# HT32F175x register map
File version: 1.0
Registers are 32-bit, read-write, reset 0x0 unless marked. A register's access mark holds for its fields unless they carry their own. Offsets are from the block's base; [hi:lo] are bit positions; {n}, {i} and the like mark numbered series.

## BFTM0
Base 0x40076000
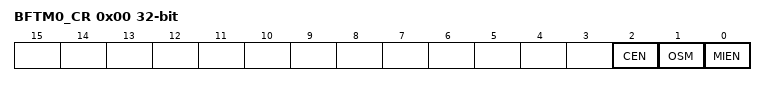
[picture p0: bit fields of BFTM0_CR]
0x00 BFTM0_CR
  [2] CEN, [1] OSM, [0] MIEN
0x04 BFTM0_SR
  [0] MIF
0x08 BFTM0_CNTR
0x0C BFTM0_CMPR
  [31:0] CMP

## BFTM1
Base 0x40077000
Registers as BFTM0 (with BFTM0 read as BFTM1).

## RTC
Base 0x4006A000
0x00 RTC_CNT
  [31:0] RTCCNT
0x04 RTC_CMP
  [31:0] RTCCMP
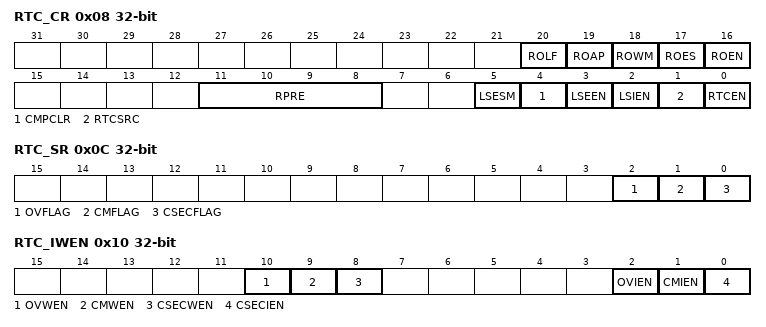
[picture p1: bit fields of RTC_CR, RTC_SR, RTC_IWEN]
0x08 RTC_CR
  [20] ROLF, [19] ROAP, [18] ROWM, [17] ROES, [16] ROEN, [11:8] RPRE, [5] LSESM, [4] CMPCLR, [3] LSEEN, [2] LSIEN, [1] RTCSRC, [0] RTCEN
0x0C RTC_SR
  [2] OVFLAG, [1] CMFLAG, [0] CSECFLAG
0x10 RTC_IWEN
  [10] OVWEN, [9] CMWEN, [8] CSECWEN, [2] OVIEN, [1] CMIEN, [0] CSECIEN

## WDT
Base 0x40068000
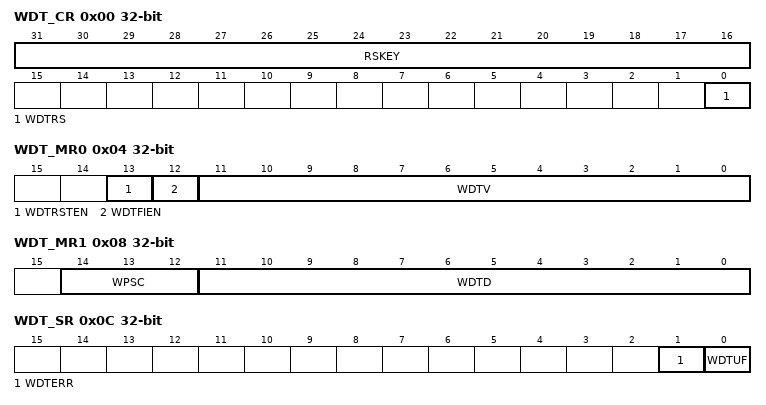
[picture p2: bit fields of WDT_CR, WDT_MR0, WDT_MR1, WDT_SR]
0x00 WDT_CR
  [31:16] RSKEY, [0] WDTRS
0x04 WDT_MR0
  [13] WDTRSTEN, [12] WDTFIEN, [11:0] WDTV
0x08 WDT_MR1
  [14:12] WPSC, [11:0] WDTD
0x0C WDT_SR
  [1] WDTERR, [0] WDTUF
0x10 WDT_PR
  [15:0] PROTECT

## I2C0
Base 0x40048000
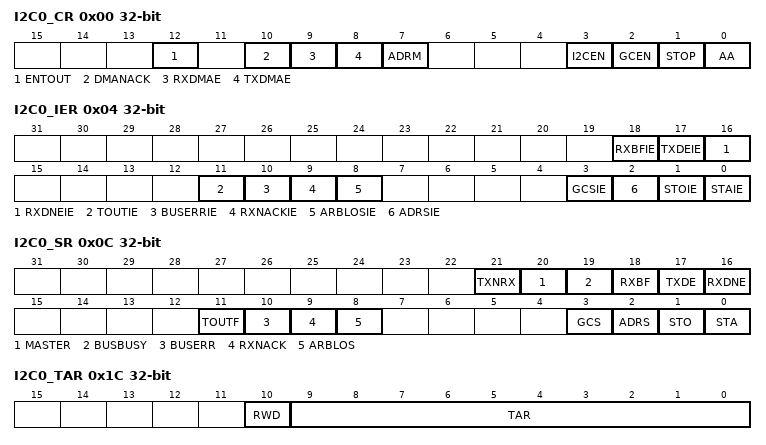
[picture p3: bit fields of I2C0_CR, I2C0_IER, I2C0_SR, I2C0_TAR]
0x00 I2C0_CR
  [12] ENTOUT, [10] DMANACK, [9] RXDMAE, [8] TXDMAE, [7] ADRM, [3] I2CEN, [2] GCEN, [1] STOP, [0] AA
0x04 I2C0_IER
  [18] RXBFIE, [17] TXDEIE, [16] RXDNEIE, [11] TOUTIE, [10] BUSERRIE, [9] RXNACKIE, [8] ARBLOSIE, [3] GCSIE, [2] ADRSIE, [1] STOIE, [0] STAIE
0x08 I2C0_ADDR
  [9:0] ADDR
0x0C I2C0_SR
  [21] TXNRX, [20] MASTER, [19] BUSBUSY, [18] RXBF, [17] TXDE, [16] RXDNE, [11] TOUTF, [10] BUSERR, [9] RXNACK, [8] ARBLOS, [3] GCS, [2] ADRS, [1] STO, [0] STA
0x10 I2C0_SHPGR
  [15:0] SHPG
0x14 I2C0_SLPGR
  [15:0] SLPG
0x18 I2C0_DR
  [7:0] DATA
0x1C I2C0_TAR
  [10] RWD, [9:0] TAR
0x20 I2C0_ADDMR
  [9:0] ADDMR
0x24 I2C0_ADDSR
  [9:0] ADDSR
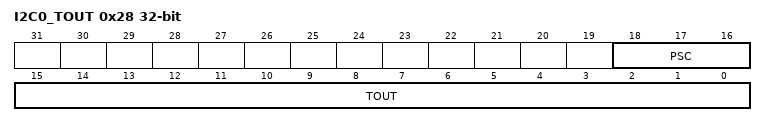
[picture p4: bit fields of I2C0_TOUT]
0x28 I2C0_TOUT
  [18:16] PSC, [15:0] TOUT

## I2C1
Base 0x40049000
Registers as I2C0 (with I2C0 read as I2C1).

## SPI0
Base 0x40004000
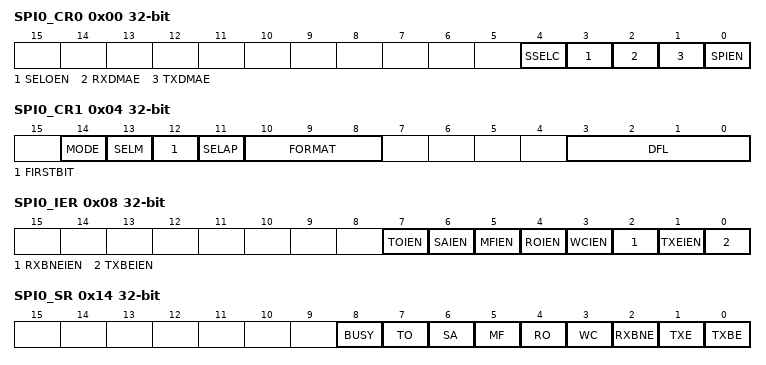
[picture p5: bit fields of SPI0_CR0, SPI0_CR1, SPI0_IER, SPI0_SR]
0x00 SPI0_CR0
  [4] SSELC, [3] SELOEN, [2] RXDMAE, [1] TXDMAE, [0] SPIEN
0x04 SPI0_CR1
  [14] MODE, [13] SELM, [12] FIRSTBIT, [11] SELAP, [10:8] FORMAT, [3:0] DFL
0x08 SPI0_IER
  [7] TOIEN, [6] SAIEN, [5] MFIEN, [4] ROIEN, [3] WCIEN, [2] RXBNEIEN, [1] TXEIEN, [0] TXBEIEN
0x0C SPI0_CPR
  [15:0] CP
0x10 SPI0_DR
  [15:0] DR
0x14 SPI0_SR
  [8] BUSY, [7] TO, [6] SA, [5] MF, [4] RO, [3] WC, [2] RXBNE, [1] TXE, [0] TXBE
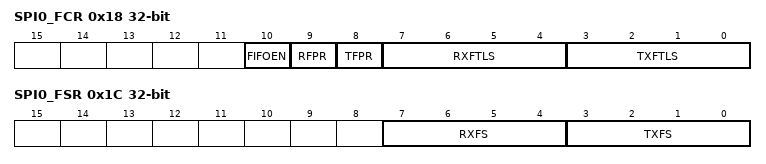
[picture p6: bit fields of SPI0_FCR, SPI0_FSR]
0x18 SPI0_FCR
  [10] FIFOEN, [9] RFPR, [8] TFPR, [7:4] RXFTLS, [3:0] TXFTLS
0x1C SPI0_FSR
  [7:4] RXFS, [3:0] TXFS
0x20 SPI0_FTOCR
  [31:0] TOC

## SPI1
Base 0x40044000
Registers as SPI0 (with SPI0 read as SPI1).

## USART0
Base 0x40000000
0x00 USART0_RBR
  [8:0] RD
0x00 USART0_TBR (USART0 view)
  [8:0] TD
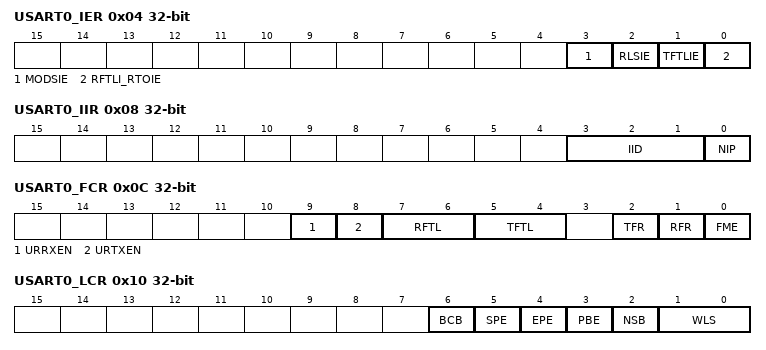
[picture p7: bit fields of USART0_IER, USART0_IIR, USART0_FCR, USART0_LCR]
0x04 USART0_IER
  [3] MODSIE, [2] RLSIE, [1] TFTLIE, [0] RFTLI_RTOIE
0x08 USART0_IIR
  [3:1] IID, [0] NIP
0x0C USART0_FCR
  [9] URRXEN, [8] URTXEN, [7:6] RFTL, [5:4] TFTL, [2] TFR, [1] RFR, [0] FME
0x10 USART0_LCR
  [6] BCB, [5] SPE, [4] EPE, [3] PBE, [2] NSB, [1:0] WLS
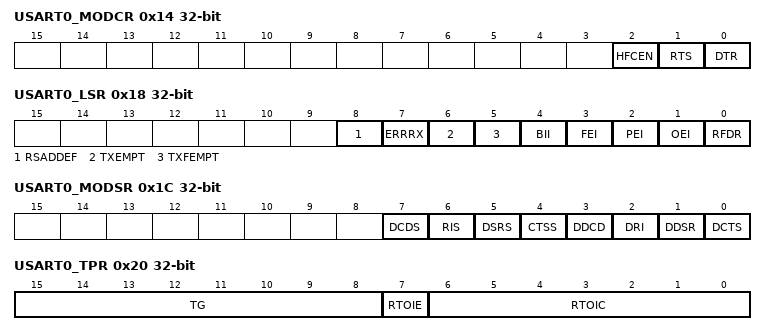
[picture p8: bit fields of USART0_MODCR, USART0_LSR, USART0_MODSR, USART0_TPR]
0x14 USART0_MODCR
  [2] HFCEN, [1] RTS, [0] DTR
0x18 USART0_LSR
  [8] RSADDEF, [7] ERRRX, [6] TXEMPT, [5] TXFEMPT, [4] BII, [3] FEI, [2] PEI, [1] OEI, [0] RFDR
0x1C USART0_MODSR
  [7] DCDS, [6] RIS, [5] DSRS, [4] CTSS, [3] DDCD, [2] DRI, [1] DDSR, [0] DCTS
0x20 USART0_TPR
  [15:8] TG, [7] RTOIE, [6:0] RTOIC
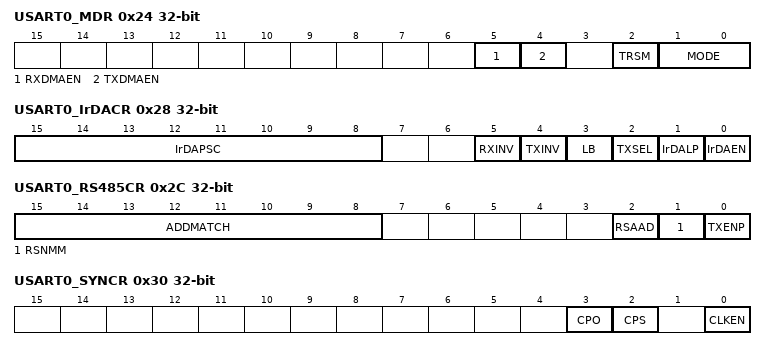
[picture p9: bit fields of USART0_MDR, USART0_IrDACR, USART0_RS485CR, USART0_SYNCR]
0x24 USART0_MDR
  [5] RXDMAEN, [4] TXDMAEN, [2] TRSM, [1:0] MODE
0x28 USART0_IrDACR
  [15:8] IrDAPSC, [5] RXINV, [4] TXINV, [3] LB, [2] TXSEL, [1] IrDALP, [0] IrDAEN
0x2C USART0_RS485CR
  [15:8] ADDMATCH, [2] RSAAD, [1] RSNMM, [0] TXENP
0x30 USART0_SYNCR
  [3] CPO, [2] CPS, [0] CLKEN
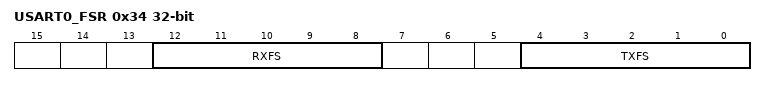
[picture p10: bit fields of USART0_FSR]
0x34 USART0_FSR
  [12:8] RXFS, [4:0] TXFS
0x38 USART0_DLR
  [15:0] BRD
0x40 USART0_DEGTSTR
  [1:0] LBM

## USART1
Base 0x40040000
Registers as USART0 (with USART0 read as USART1).

## SCI
Base 0x40043000
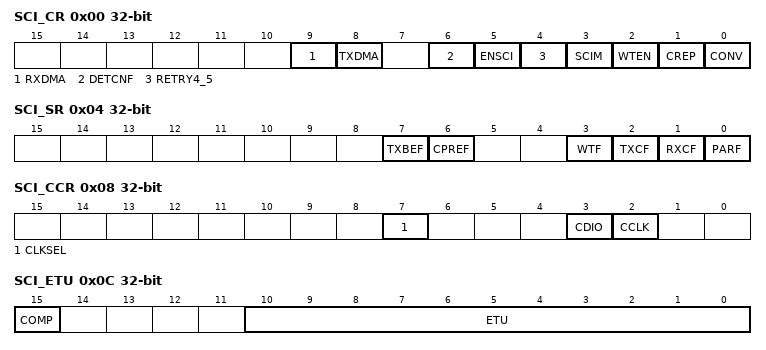
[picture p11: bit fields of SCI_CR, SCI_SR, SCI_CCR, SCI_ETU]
0x00 SCI_CR
  [9] RXDMA, [8] TXDMA, [6] DETCNF, [5] ENSCI, [4] RETRY4_5, [3] SCIM, [2] WTEN, [1] CREP, [0] CONV
0x04 SCI_SR
  [7] TXBEF, [6] CPREF, [3] WTF, [2] TXCF, [1] RXCF, [0] PARF
0x08 SCI_CCR
  [7] CLKSEL, [3] CDIO, [2] CCLK
0x0C SCI_ETU
  [15] COMP, [10:0] ETU
0x10 SCI_GT
  [8:0] GT
0x14 SCI_WT
  [23:0] WT
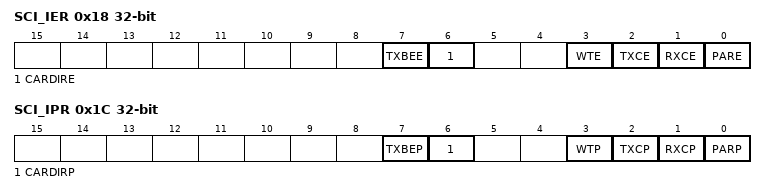
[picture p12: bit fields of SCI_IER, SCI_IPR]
0x18 SCI_IER
  [7] TXBEE, [6] CARDIRE, [3] WTE, [2] TXCE, [1] RXCE, [0] PARE
0x1C SCI_IPR
  [7] TXBEP, [6] CARDIRP, [3] WTP, [2] TXCP, [1] RXCP, [0] PARP
0x20 SCI_TXB
  [7:0] TB
0x24 SCI_RXB
  [7:0] RB
0x28 SCI_PSC
  [5:0] PSC

## USB
Base 0x4004E000
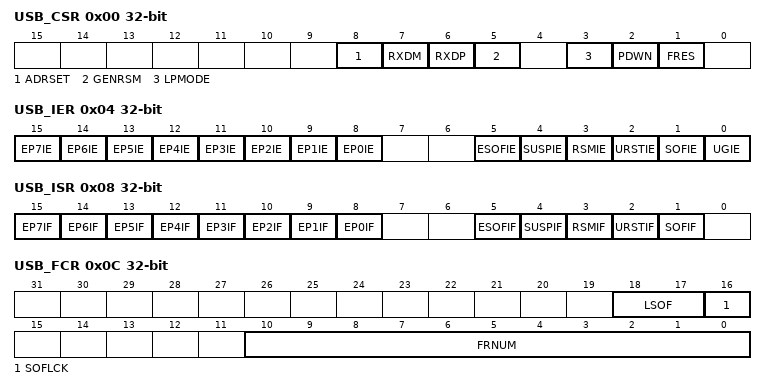
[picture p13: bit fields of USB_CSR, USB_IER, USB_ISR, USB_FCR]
0x00 USB_CSR
  [8] ADRSET, [7] RXDM, [6] RXDP, [5] GENRSM, [3] LPMODE, [2] PDWN, [1] FRES
0x04 USB_IER
  [n+8] EP{n}IE (n=0..7), [5] ESOFIE, [4] SUSPIE, [3] RSMIE, [2] URSTIE, [1] SOFIE, [0] UGIE
0x08 USB_ISR
  [n+8] EP{n}IF (n=0..7), [5] ESOFIF, [4] SUSPIF, [3] RSMIF, [2] URSTIF, [1] SOFIF
0x0C USB_FCR
  [18:17] LSOF, [16] SOFLCK, [10:0] FRNUM
0x10 USB_DEVAR
  [6:0] DEVA
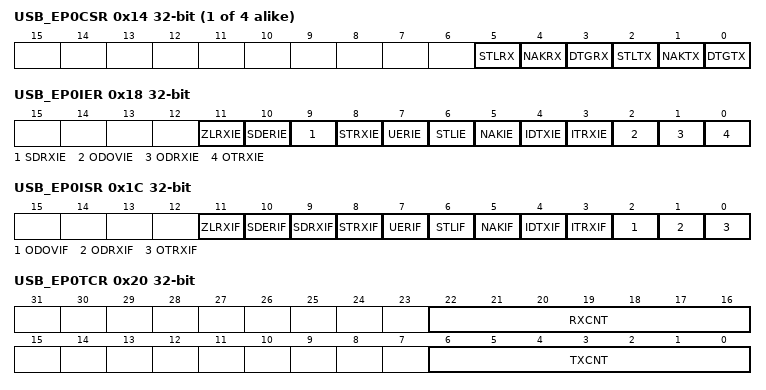
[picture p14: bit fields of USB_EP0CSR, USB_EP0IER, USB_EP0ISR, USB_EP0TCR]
{0x14+0x14*i} USB_EP{i}CSR (i=0..3)
  [5] STLRX, [4] NAKRX, [3] DTGRX, [2] STLTX, [1] NAKTX, [0] DTGTX
0x18 USB_EP0IER
  [11] ZLRXIE, [10] SDERIE, [9] SDRXIE, [8] STRXIE, [7] UERIE, [6] STLIE, [5] NAKIE, [4] IDTXIE, [3] ITRXIE, [2] ODOVIE, [1] ODRXIE, [0] OTRXIE
0x1C USB_EP0ISR
  [11] ZLRXIF, [10] SDERIF, [9] SDRXIF, [8] STRXIF, [7] UERIF, [6] STLIF, [5] NAKIF, [4] IDTXIF, [3] ITRXIF, [2] ODOVIF, [1] ODRXIF, [0] OTRXIF
0x20 USB_EP0TCR
  [22:16] RXCNT, [6:0] TXCNT
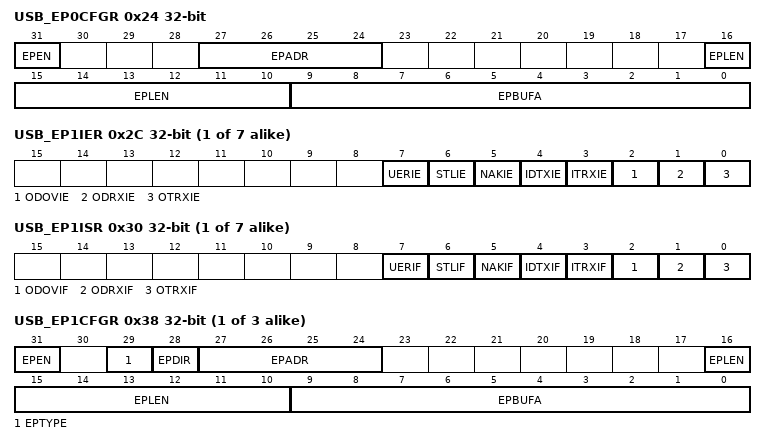
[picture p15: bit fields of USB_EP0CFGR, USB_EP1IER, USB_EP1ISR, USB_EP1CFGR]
0x24 USB_EP0CFGR
  [31] EPEN, [27:24] EPADR, [16:10] EPLEN, [9:0] EPBUFA
{0x18+0x14*i} USB_EP{i}IER (i=1..7)
  [7] UERIE, [6] STLIE, [5] NAKIE, [4] IDTXIE, [3] ITRXIE, [2] ODOVIE, [1] ODRXIE, [0] OTRXIE
{0x1C+0x14*i} USB_EP{i}ISR (i=1..7)
  [7] UERIF, [6] STLIF, [5] NAKIF, [4] IDTXIF, [3] ITRXIF, [2] ODOVIF, [1] ODRXIF, [0] OTRXIF
{0x20+0x14*i} USB_EP{i}TCR (i=1..3)
  [8:0] TCNT
{0x24+0x14*i} USB_EP{i}CFGR (i=1..3)
  [31] EPEN, [29] EPTYPE, [28] EPDIR, [27:24] EPADR, [16:10] EPLEN, [9:0] EPBUFA
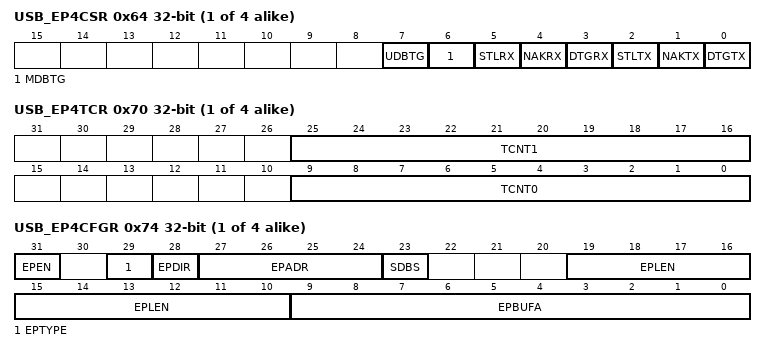
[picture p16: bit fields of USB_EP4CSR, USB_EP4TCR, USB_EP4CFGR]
{0x14+0x14*i} USB_EP{i}CSR (i=4..7)
  [7] UDBTG, [6] MDBTG, [5] STLRX, [4] NAKRX, [3] DTGRX, [2] STLTX, [1] NAKTX, [0] DTGTX
{0x20+0x14*i} USB_EP{i}TCR (i=4..7)
  [25:16] TCNT1, [9:0] TCNT0
{0x24+0x14*i} USB_EP{i}CFGR (i=4..7)
  [31] EPEN, [29] EPTYPE, [28] EPDIR, [27:24] EPADR, [23] SDBS, [19:10] EPLEN, [9:0] EPBUFA

## PDMA
Base 0x40090000
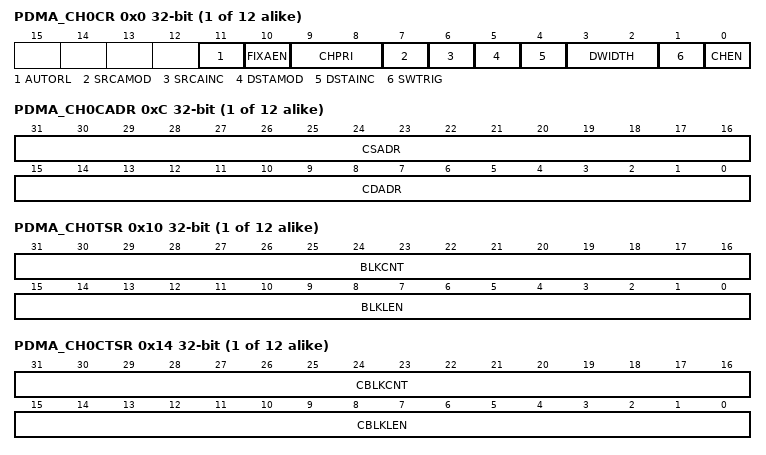
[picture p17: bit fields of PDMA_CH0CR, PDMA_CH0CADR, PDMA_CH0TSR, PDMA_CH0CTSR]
{0x0+0x18*i} PDMA_CH{i}CR (i=0..11)
  [11] AUTORL, [10] FIXAEN, [9:8] CHPRI, [7] SRCAMOD, [6] SRCAINC, [5] DSTAMOD, [4] DSTAINC, [3:2] DWIDTH, [1] SWTRIG, [0] CHEN
{0x4+0x18*i} PDMA_CH{i}SADR (i=0..11)
  [31:0] SADR
{0x8+0x18*i} PDMA_CH{i}DADR (i=0..11)
  [31:0] DADR
{0xC+0x18*i} PDMA_CH{i}CADR (i=0..11)
  [31:16] CSADR, [15:0] CDADR
{0x10+0x18*i} PDMA_CH{i}TSR (i=0..11)
  [31:16] BLKCNT, [15:0] BLKLEN
{0x14+0x18*i} PDMA_CH{i}CTSR (i=0..11)
  [31:16] CBLKCNT, [15:0] CBLKLEN
0x120 PDMA_ISR0
  [5n+4] TEISTA{n} (n=0..5), [5n+3] TCISTA{n} (n=0..5), [5n+2] HTISTA{n} (n=0..5), [5n+1] BEISTA{n} (n=0..5), [5n] GEISTA{n} (n=0..5)
0x124 PDMA_ISR1
  [5n-26] TEISTA{n} (n=6..11), [5n-27] TCISTA{n} (n=6..11), [5n-28] HTISTA{n} (n=6..11), [5n-29] BEISTA{n} (n=6..11), [5n-30] GEISTA{n} (n=6..11)
0x128 PDMA_ISCR0
  [5n+4] TEICLR{n} (n=0..5), [5n+3] TCICLR{n} (n=0..5), [5n+2] HTICLR{n} (n=0..5), [5n+1] BEICLR{n} (n=0..5), [5n] GEICLR{n} (n=0..5)
0x12C PDMA_ISCR1
  [5n-26] TEICLR{n} (n=6..11), [5n-27] TCICLR{n} (n=6..11), [5n-28] HTICLR{n} (n=6..11), [5n-29] BEICLR{n} (n=6..11), [5n-30] GEICLR{n} (n=6..11)
0x130 PDMA_IER0
  [5n+4] TEIE{n} (n=0..5), [5n+3] TCIE{n} (n=0..5), [5n+2] HTIE{n} (n=0..5), [5n+1] BEIE{n} (n=0..5), [5n] GEIE{n} (n=0..5)
0x134 PDMA_IER1
  [5n-26] TEIE{n} (n=6..11), [5n-27] TCIE{n} (n=6..11), [5n-28] HTIE{n} (n=6..11), [5n-29] BEIE{n} (n=6..11), [5n-30] GEIE{n} (n=6..11)
